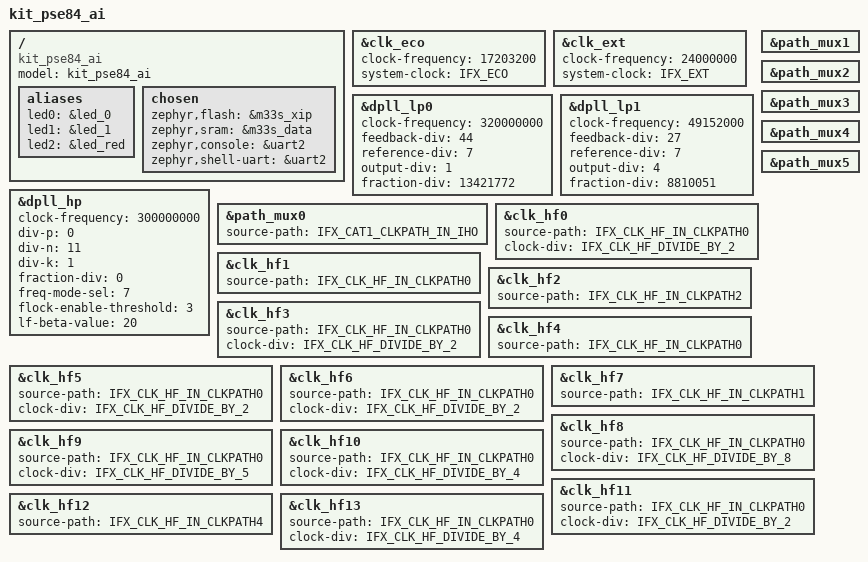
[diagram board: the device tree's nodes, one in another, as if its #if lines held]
/*
 * Copyright (c) 2025 Infineon Technologies AG,
 * or an affiliate of Infineon Technologies AG.
 *
 * SPDX-License-Identifier: Apache-2.0
 */

/dts-v1/;
#include <infineon/edge/mpns/pse846gps2dbzc4a_s.dtsi>
#include <infineon/edge/pse84/pse84.cm33.dtsi>
#include <infineon/edge/pse84/system_clocks.dtsi>

#include "kit_pse84_ai_common.dtsi"
#include "kit_pse84_ai_memory_map.dtsi"

/ {
	model = "kit_pse84_ai";
	compatible = "kit_pse84_ai";

	aliases {
		led0 = &led_0;
		led1 = &led_1;
		led2 = &led_red;
	};

	chosen {
		zephyr,flash = &m33s_xip;
		zephyr,sram = &m33s_data;
		zephyr,console = &uart2;
		zephyr,shell-uart = &uart2;
	};
};

/* For the dpll clocks declared below
 * The clock-frequency value is here for dts reference, but
 * it does not affect the frequency set by the clock_control
 * driver. That is decided by the rest of the variables in
 * this block. They result in the set clock-frequency. For other
 * frequencies, they need to be calculated separately and
 * entered into the devicetree dpll_* block.
 */
&clk_eco {
	clock-frequency = <17203200>;
	system-clock = <IFX_ECO>;
	status = "okay";
};

&clk_ext {
	clock-frequency = <24000000>;
	system-clock = <IFX_EXT>;
	status = "okay";
};

/*
 * Clock source selection — change exactly ONE line to switch:
 *
 *   #define DPLL_LP0_CLKSRC_IHO -> IHO  50.0000 MHz (fractional)
 *   #define DPLL_LP0_CLKSRC_ECO -> ECO  17.2032 MHz (fractional)
 *   #define DPLL_LP0_CLKSRC_EXT -> EXT  24.0000 MHz (integer) <- ACTIVE
 *
 * Fout = (Fref / Q) * (P + frac_div / 2^24) / N,  target = 320 MHz
 */
#define DPLL_LP0_CLKSRC_IHO

/* ── dpll_lp0 — clock path 0, 320 MHz ─────────────────────────────────── */
#if defined(DPLL_LP0_CLKSRC_IHO)
/* IHO 50 MHz: (50M/7) * (44 + 13421772/2^24) / 1 ≈ 320.000 MHz */
&dpll_lp0 {
	status = "okay";
	clock-frequency = <320000000>;
	feedback-div    = <44>;         /* P */
	reference-div   = <7>;          /* Q */
	output-div      = <1>;          /* N */
	fraction-div    = <13421772>;
};

#elif defined(DPLL_LP0_CLKSRC_ECO)
/* ECO 17.2032 MHz: (17.2032M/2) * (37 + 3395389/2^24) / 1 ≈ 320.000 MHz */
&dpll_lp0 {
	status = "okay";
	clock-frequency = <320000000>;
	feedback-div    = <37>;         /* P */
	reference-div   = <2>;          /* Q */
	output-div      = <1>;          /* N */
	fraction-div    = <3395389>;
};

#elif defined(DPLL_LP0_CLKSRC_EXT)
/* EXT 24 MHz: (24M/3) * (40 + 0) / 1 = 320.000 MHz */
&dpll_lp0 {
	status = "okay";
	clock-frequency = <320000000>;
	feedback-div    = <40>;         /* P */
	reference-div   = <3>;          /* Q */
	output-div      = <1>;          /* N */
	fraction-div    = <0>;
};

#else
#error "No clock source defined. Set CLKSRC_IHO, CLKSRC_ECO, or CLKSRC_EXT."
#endif

/* This dpll_lp1 is on "clock path" 1. So HF clocks sourced
 * from *_CLKPATH1 will receive this frequency instead, when the
 * dpll_lp1 is set to "okay".
 */
&dpll_lp1 {
	status = "okay";
	clock-frequency = <49152000>;

	feedback-div  = <27>;
	reference-div = <7>;
	output-div    = <4>;
	fraction-div  = <8810051>;
};

/* This dpll_hp is on "clock path" 2. So HF clocks sourced
 * from *_CLKPATH2 will receive this frequency, when the
 * dpll_hp is set to "okay".
 */
&dpll_hp {
	status = "okay";
	clock-frequency = <300000000>;

	div-p = <0>;
	div-n = <11>;
	div-k = <1>;
	fraction-div = <0>;
	freq-mode-sel = <7>;
	flock-enable-threshold = <3>;
	lf-beta-value = <20>;
};

/* path_mux0 must match the selected source above */
&path_mux0 {
	#if defined(DPLL_LP0_CLKSRC_IHO)
	source-path = <IFX_CAT1_CLKPATH_IN_IHO>;
	#elif defined(DPLL_LP0_CLKSRC_ECO)
	source-path = <IFX_CAT1_CLKPATH_IN_ECO>;
	#elif defined(DPLL_LP0_CLKSRC_EXT)
	source-path = <IFX_CAT1_CLKPATH_IN_EXT>;
	#endif

	status = "okay";
};

&path_mux1 {
	status = "okay";
};

&path_mux2 {
	status = "okay";
};

&path_mux3 {
	status = "okay";
};

&path_mux4 {
	status = "okay";
};

&path_mux5 {
	status = "okay";
};

&clk_hf0 {
	source-path = <IFX_CLK_HF_IN_CLKPATH0>;
	clock-div = <IFX_CLK_HF_DIVIDE_BY_2>;
	status = "okay";
};

&clk_hf1 {
	source-path = <IFX_CLK_HF_IN_CLKPATH0>;
	status = "okay";
};

&clk_hf2 {
	source-path = <IFX_CLK_HF_IN_CLKPATH2>;
	status = "okay";
};

&clk_hf3 {
	source-path = <IFX_CLK_HF_IN_CLKPATH0>;
	clock-div = <IFX_CLK_HF_DIVIDE_BY_2>;
	status = "okay";
};

&clk_hf4 {
	source-path = <IFX_CLK_HF_IN_CLKPATH0>;
	status = "okay";
};

&clk_hf5 { /* DPLL_LP0 (320 MHz) / 2 = HF5 (160 MHz) */
	source-path = <IFX_CLK_HF_IN_CLKPATH0>;
	clock-div = <IFX_CLK_HF_DIVIDE_BY_2>;
	status = "okay";
};

&clk_hf6 {
	source-path = <IFX_CLK_HF_IN_CLKPATH0>;
	clock-div = <IFX_CLK_HF_DIVIDE_BY_2>;
	status = "okay";
};

&clk_hf7 {
	source-path = <IFX_CLK_HF_IN_CLKPATH1>;
	status = "okay";
};

&clk_hf8 {
	source-path = <IFX_CLK_HF_IN_CLKPATH0>;
	clock-div = <IFX_CLK_HF_DIVIDE_BY_8>;
	status = "okay";
};

&clk_hf9 {
	source-path = <IFX_CLK_HF_IN_CLKPATH0>;
	clock-div = <IFX_CLK_HF_DIVIDE_BY_5>;
	status = "okay";
};

&clk_hf10 {
	source-path = <IFX_CLK_HF_IN_CLKPATH0>;
	clock-div = <IFX_CLK_HF_DIVIDE_BY_4>;
	status = "okay";
};

&clk_hf11 {
	source-path = <IFX_CLK_HF_IN_CLKPATH0>;
	clock-div = <IFX_CLK_HF_DIVIDE_BY_2>;
	status = "okay";
};

&clk_hf12 {
	source-path = <IFX_CLK_HF_IN_CLKPATH4>;
	status = "okay";
};

&clk_hf13 {
	source-path = <IFX_CLK_HF_IN_CLKPATH0>;
	clock-div = <IFX_CLK_HF_DIVIDE_BY_4>;
	status = "okay";
};
